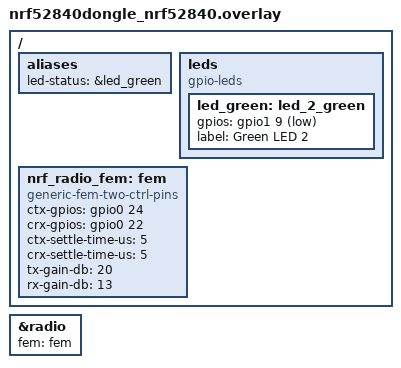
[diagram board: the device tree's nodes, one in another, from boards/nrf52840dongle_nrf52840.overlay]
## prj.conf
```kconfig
CONFIG_BT=y
CONFIG_BT_HCI_RAW=y

CONFIG_USB_DEVICE_STACK=y
CONFIG_USB_DEVICE_PID=0x000B
CONFIG_USB_DEVICE_BLUETOOTH=y
CONFIG_USB_DEVICE_INITIALIZE_AT_BOOT=n

# We dont want any console or CDC ACM that may cause BlueZ to not detect hci_usb
CONFIG_SERIAL=n
CONFIG_CONSOLE=n
CONFIG_UART_CONSOLE=n

# FEM (Front End Module) support for 2401C PA/LNA
CONFIG_MPSL=y
CONFIG_MPSL_FEM_SIMPLE_GPIO=y

# GPIO for LED control
CONFIG_GPIO=y
```

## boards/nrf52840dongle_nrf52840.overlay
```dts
/*
 * Devicetree overlay for HoLyiot 21017-52840+PA module
 * Configures FEM (2401C PA/LNA) and LED
 */

/ {
	/* Define the green LED alias */
	aliases {
		led-status = &led_green;
	};

	leds {
		compatible = "gpio-leds";
		led_green: led_2_green {
			gpios = <&gpio1 9 GPIO_ACTIVE_LOW>;  /* R1 = P1.09 */
			label = "Green LED 2";
		};
	};
};

/* FEM configuration for 2401C PA/LNA */
&radio {
	fem = <&fem>;
};

/ {
	nrf_radio_fem: fem: fem {
		compatible = "generic-fem-two-ctrl-pins";
		/* Per schematic: TXEN -> AD20 (P0.24), RXEN -> AD18 (P0.22) */
		ctx-gpios = <&gpio0 24 GPIO_ACTIVE_HIGH>;  /* TXEN */
		crx-gpios = <&gpio0 22 GPIO_ACTIVE_HIGH>;  /* RXEN */
		ctx-settle-time-us = <5>;
		crx-settle-time-us = <5>;
		tx-gain-db = <20>;  /* PA gain in dB */
		rx-gain-db = <13>;  /* LNA gain in dB */
	};
};
```

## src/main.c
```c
/*
 * Copyright (c) 2018 Intel Corporation
 *
 * SPDX-License-Identifier: Apache-2.0
 */

#include <zephyr/kernel.h>
#include <zephyr/sys/printk.h>
#include <zephyr/usb/usb_device.h>
#include <zephyr/usb/usbd.h>
#include <zephyr/drivers/gpio.h>

/* Green LED - indicates software is running */
#define LED_STATUS_NODE DT_ALIAS(led_status)

#if DT_NODE_EXISTS(LED_STATUS_NODE)
static const struct gpio_dt_spec led_status = GPIO_DT_SPEC_GET(LED_STATUS_NODE, gpios);
#endif

#if defined(CONFIG_USB_DEVICE_STACK_NEXT)
#include <sample_usbd.h>

static int enable_usb_device_next(void)
{
	struct usbd_context *sample_usbd = sample_usbd_init_device(NULL);

	if (sample_usbd == NULL) {
		printk("Failed to initialize USB device");
		return -ENODEV;
	}

	return usbd_enable(sample_usbd);
}
#endif /* CONFIG_USB_DEVICE_STACK_NEXT */

static void led_status_init(void)
{
#if DT_NODE_EXISTS(LED_STATUS_NODE)
	if (!gpio_is_ready_dt(&led_status)) {
		printk("LED GPIO not ready\n");
		return;
	}

	if (gpio_pin_configure_dt(&led_status, GPIO_OUTPUT_ACTIVE) < 0) {
		printk("Failed to configure LED GPIO\n");
		return;
	}

	/* Turn on green LED to indicate software is running */
	gpio_pin_set_dt(&led_status, 1);
	printk("Status LED enabled\n");
#endif
}

int main(void)
{
	int ret;

	/* Enable green LED to indicate software is up and running */
	led_status_init();

#if defined(CONFIG_USB_DEVICE_STACK_NEXT)
	ret = enable_usb_device_next();
#else
	ret = usb_enable(NULL);
#endif

	if (ret != 0) {
		printk("Failed to enable USB");
		return 0;
	}

	printk("Bluetooth over USB sample\n");
	return 0;
}
```
